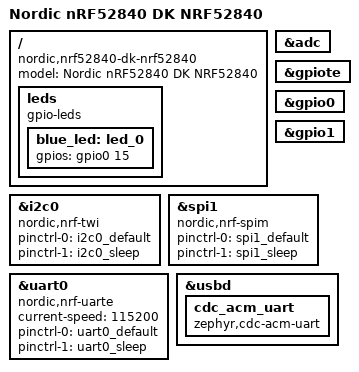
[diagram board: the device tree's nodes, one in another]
/*
 * Copyright (c) 2021 The ZMK Contributors
 *
 * SPDX-License-Identifier: MIT
 */

#include "nice_nano-pinctrl.dtsi"

/ {
	model = "Nordic nRF52840 DK NRF52840";
	compatible = "nordic,nrf52840-dk-nrf52840";


    leds {
        compatible = "gpio-leds";
        blue_led: led_0 {
            gpios = <&gpio0 15 GPIO_ACTIVE_HIGH>;
        };
    };
};

&adc {
    status = "okay";
};

&gpiote {
    status = "okay";
};

&gpio0 {
    status = "okay";
};

&gpio1 {
    status = "okay";
};

&i2c0 {
    compatible = "nordic,nrf-twi";
    pinctrl-0 = <&i2c0_default>;
    pinctrl-1 = <&i2c0_sleep>;
    pinctrl-names = "default", "sleep";
};

&spi1 {
    compatible = "nordic,nrf-spim";
    pinctrl-0 = <&spi1_default>;
    pinctrl-1 = <&spi1_sleep>;
    pinctrl-names = "default", "sleep";
};

&uart0 {
    compatible = "nordic,nrf-uarte";
    current-speed = <115200>;
    pinctrl-0 = <&uart0_default>;
    pinctrl-1 = <&uart0_sleep>;
    pinctrl-names = "default", "sleep";
};

&usbd {
    status = "okay";
    cdc_acm_uart: cdc_acm_uart {
        compatible = "zephyr,cdc-acm-uart";
    };
};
